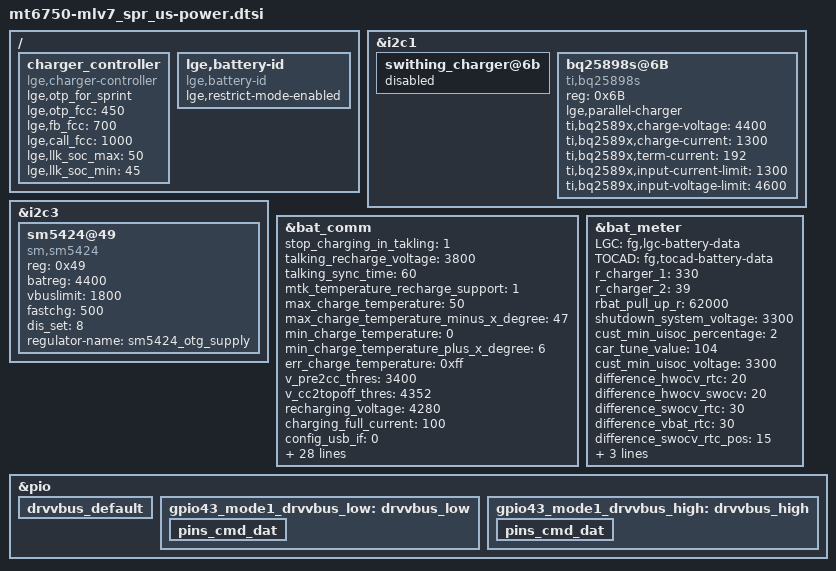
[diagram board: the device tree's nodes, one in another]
/*
 * LG Electronics LS7 power device tree source
 *
 * Copyright (c) 2017 LG Electronics Co., Ltd.
 *              http://www.lge.com
 *
 */

/* battery profile */
#include "../battery_LGE_4500mAh_BL-T30.dtsi"

&i2c1 {
	swithing_charger@6b {
		status = "disabled";
	 };

	bq25898s@6B {
		status = "okay";
		compatible = "ti,bq25898s";
		reg = <0x6B>;
		lge,parallel-charger;
		ti,bq2589x,charge-voltage = <4400>;
		ti,bq2589x,charge-current = <1300>;
		ti,bq2589x,term-current = <192>;
		ti,bq2589x,input-current-limit = <1300>;
		ti,bq2589x,input-voltage-limit = <4600>;
	};
};

&i2c3 {
	sm5424@49 {
		status = "okay";
		compatible = "sm,sm5424";
		reg = <0x49>;

		batreg = <4400>;
		vbuslimit = <1800>;
		fastchg = <500>;
		dis_set = <8>;

		regulator-name = "sm5424_otg_supply";
	};
};

&bat_comm {
			/* cust_charging.h */
			/* stop charging while in talking mode */
			stop_charging_in_takling = <1 >;
			talking_recharge_voltage = <3800 >;
			talking_sync_time = <60 >;

			/* Battery Temperature Protection */
			mtk_temperature_recharge_support = <1 >;
			max_charge_temperature = <50 >;
			max_charge_temperature_minus_x_degree = <47 >;
			min_charge_temperature = <0 >;
			min_charge_temperature_plus_x_degree = <6 >;
			err_charge_temperature = <0xff >;

			/* Linear Charging Threshold */
			v_pre2cc_thres = <3400 >;	/* unit: mV */
			v_cc2topoff_thres = <4352 >;
			recharging_voltage = <4280 >;
			charging_full_current = <100 >;	/* unit: mA */

			/* Charging Current Setting */
			config_usb_if = <0 >;
			usb_charger_current_suspend = <0 >;	/* Unit: 0.01 mA */
			usb_charger_current_unconfigured = <7000 >;	/* Unit: 0.01 mA */
			usb_charger_current_configured = <50000 >;	/* Unit: 0.01 mA */
			usb_charger_current = <50000 >;	/* Unit: 0.01 mA */
			ac_charger_current = <180000 >;	/* Unit: 0.01 mA */
			ac_charger_input_current = <180000 >;	/* Unit: 0.01 mA */
			non_std_ac_charger_current = <50000 >;	/* Unit: 0.01 mA */
			charging_host_charger_current = <150000 >;	/* Unit: 0.01 mA */
			apple_0_5a_charger_current = <50000 >;	/* Unit: 0.01 mA */
			apple_1_0a_charger_current = <100000 >;	/* Unit: 0.01 mA */
			apple_2_1a_charger_current = <210000 >;	/* Unit: 0.01 mA */

			/* charger error check */
			v_charger_enable = <0 >;	/* 1:on , 0:off */
			v_charger_max = <10500 >;	/* unit: mV */
			v_charger_min = <4400 >;

			/*  Tracking TIME */
			onehundred_percent_tracking_time = <10 >;	/* Unit: second */
			npercent_tracking_time = <20 >;	/* Unit: second */
			sync_to_real_tracking_time = <60 >;	/* Unit: second */
			v_0percent_tracking = <3450 >;	/* Unit: mV */

			/* High battery support */
			high_battery_voltage_support = <1 >;

			mtk_pump_express_plus_support = <1 >;
			ta_start_battery_soc = <1 >;
			ta_stop_battery_soc = <95 >;
			ta_ac_charging_current = <260000 >;

			ta_ac_12v_input_current = <180000 >;
			ta_ac_9v_input_current = <180000 >;
			ta_ac_7v_input_current = <180000 >;

			ta_9v_support = <1 >;
			ta_12v_support = <0 >;
};

/* fuel gauge */
&bat_meter {
	LGC = "fg,lgc-battery-data";
	TOCAD = "fg,tocad-battery-data";

	/* cust_battery_meter.h */
	r_charger_1 = <330 >;
	r_charger_2 = <39 >;

	rbat_pull_up_r = <62000 >;

	shutdown_system_voltage = <3300 >;
	/* K6 don't use this option */
	cust_min_uisoc_percentage = <2>;
	car_tune_value = <104 >;
	/* keep min uisoc until voltage less than customization voltage of min uisoc */
	cust_min_uisoc_voltage = <3300 >;

	/* fg 2.0 */
	difference_hwocv_rtc = <20 >;
	difference_hwocv_swocv = <20 >;
	difference_swocv_rtc = <30 >;
	difference_vbat_rtc = <30 >;
	difference_swocv_rtc_pos = <15 >;
	batterypseudo100 = <94 >;
	batterypseudo1 = <1 >;
	embedded_battery =<1 >;
};

/ {
	charger_controller: charger_controller {
		status = "ok";
		compatible = "lge,charger-controller";

		lge,otp_for_sprint;
		lge,otp_fcc = <450>;
		lge,fb_fcc = <700>;
		lge,call_fcc = <1000>;

		lge,llk_soc_max = <50>;
		lge,llk_soc_min = <45>;
	};
};

/ {
	lge,battery-id{
		compatible = "lge,battery-id";
		lge,restrict-mode-enabled;
	};
};

&pio {
	drvvbus_default: drvvbus_default {
	};

	gpio43_mode1_drvvbus_low: drvvbus_low {
		pins_cmd_dat {
			/delete-property/	pins;
			/delete-property/	slew-rate;
			/delete-property/	output-low;
		};
	};

	gpio43_mode1_drvvbus_high: drvvbus_high {
		pins_cmd_dat {
			/delete-property/	pins;
			/delete-property/	slew-rate;
			/delete-property/	output-high;
		};
	};
};
